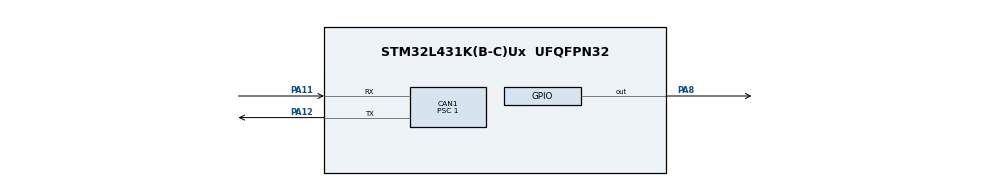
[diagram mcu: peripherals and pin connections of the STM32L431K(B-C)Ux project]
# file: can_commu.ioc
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CAN1.BS1=CAN_BS1_6TQ
CAN1.CalculateBaudRate=500000
CAN1.CalculateTimeBit=2000.00
CAN1.CalculateTimeQuantum=250.0
CAN1.Prescaler=1
Mcu.Family=STM32L4
Mcu.Name=STM32L431K(B-C)Ux
Mcu.Package=UFQFPN32
NVIC.CAN1_RX0_IRQn=true\:0\:0\:false\:false\:true\:true\:true
NVIC.CAN1_TX_IRQn=true\:0\:0\:false\:false\:true\:true\:true
NVIC.PriorityGroup=NVIC_PRIORITYGROUP_4
PA11.Mode=CAN_Activate
PA11.Signal=CAN1_RX
PA12.Mode=CAN_Activate
PA12.Signal=CAN1_TX
PA8.Signal=GPIO_Output
ProjectManager.HeapSize=0x200
ProjectManager.StackSize=0x400
ProjectManager.TargetToolchain=STM32CubeIDE
RCC.HSE_VALUE=8000000
RCC.HSI48_VALUE=48000000
RCC.HSI_VALUE=16000000
RCC.LSE_VALUE=32768
RCC.MSI_VALUE=4000000
RCC.VCOOutputFreq_Value=32000000
board=custom

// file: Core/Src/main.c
/* USER CODE BEGIN Header */
/**
  ******************************************************************************
  * @file           : main.c
  * @brief          : Main program body
  ******************************************************************************
  * @attention
  *
  * <h2><center>&copy; Copyright (c) 2024 STMicroelectronics.
  * All rights reserved.</center></h2>
  *
  * This software component is licensed by ST under BSD 3-Clause license,
  * the "License"; You may not use this file except in compliance with the
  * License. You may obtain a copy of the License at:
  *                        opensource.org/licenses/BSD-3-Clause
  *
  ******************************************************************************
  */
/* USER CODE END Header */
#include "main.h"

CAN_HandleTypeDef hcan1;

/* USER CODE BEGIN PV */
uint8_t RxData[8]; //our buffer to receive data
/* USER CODE END PV */

void SystemClock_Config(void);
static void MX_GPIO_Init(void);
static void MX_CAN1_Init(void);

int main(void)
{

  /* MCU Configuration--------------------------------------------------------*/

  /* Reset of all peripherals, Initializes the Flash interface and the Systick. */
  HAL_Init();

  /* Configure the system clock */
  SystemClock_Config();

  /* Initialize all configured peripherals */
  MX_GPIO_Init();
  MX_CAN1_Init();
  /* USER CODE BEGIN 2 */
  HAL_GPIO_WritePin(GPIOA, GPIO_PIN_8, GPIO_PIN_RESET);
  CAN_FilterTypeDef sFilterConfig ;
  sFilterConfig.FilterMode = CAN_FILTERMODE_IDMASK;
  sFilterConfig.FilterScale = CAN_FILTERSCALE_32BIT;
  sFilterConfig.FilterIdHigh = 0;
  sFilterConfig.FilterIdLow = 0;
  sFilterConfig.FilterMaskIdHigh = 0;
  sFilterConfig.FilterMaskIdLow = 0;
  sFilterConfig.FilterFIFOAssignment = CAN_RX_FIFO0;
  sFilterConfig.FilterActivation = ENABLE;
  sFilterConfig.FilterBank = 1;

  HAL_CAN_ConfigFilter(&hcan1, &sFilterConfig);
  HAL_CAN_Start(&hcan1);
  HAL_CAN_ActivateNotification(&hcan1, CAN_IT_RX_FIFO0_MSG_PENDING);

  /* CAN Tx Message */
  CAN_TxHeaderTypeDef TxHeader;
  uint8_t TxData[8] = {0x01, 0x02, 0x03, 0x04, 0x05, 0x06, 0x07, 0x08};

  TxHeader.StdId = 0x123; // Example standard ID
  TxHeader.IDE = CAN_ID_STD; // Use standard identifier
  TxHeader.RTR = CAN_RTR_DATA; // Data frame
  TxHeader.DLC = 8; // Data length is 8 bytes

  uint32_t TxMailbox = CAN_TX_MAILBOX0;

  /* USER CODE END 2 */

  /* Infinite loop */
  while (1)
  {

    /* USER CODE BEGIN 3 */
//	  HAL_CAN_AddTxMessage(&hcan1, &TxHeader, TxData, &TxMailbox);
//	  HAL_Delay(1000); // Delay between transmissions

  }
  /* USER CODE END 3 */
}

void SystemClock_Config(void)
{
  RCC_OscInitTypeDef RCC_OscInitStruct = {0};
  RCC_ClkInitTypeDef RCC_ClkInitStruct = {0};

  /** Configure the main internal regulator output voltage
  */
  if (HAL_PWREx_ControlVoltageScaling(PWR_REGULATOR_VOLTAGE_SCALE1) != HAL_OK)
  {
    Error_Handler();
  }
  /** Initializes the RCC Oscillators according to the specified parameters
  * in the RCC_OscInitTypeDef structure.
  */
  RCC_OscInitStruct.OscillatorType = RCC_OSCILLATORTYPE_MSI;
  RCC_OscInitStruct.MSIState = RCC_MSI_ON;
  RCC_OscInitStruct.MSICalibrationValue = 0;
  RCC_OscInitStruct.MSIClockRange = RCC_MSIRANGE_6;
  RCC_OscInitStruct.PLL.PLLState = RCC_PLL_NONE;
  if (HAL_RCC_OscConfig(&RCC_OscInitStruct) != HAL_OK)
  {
    Error_Handler();
  }
  /** Initializes the CPU, AHB and APB buses clocks
  */
  RCC_ClkInitStruct.ClockType = RCC_CLOCKTYPE_HCLK|RCC_CLOCKTYPE_SYSCLK
                              |RCC_CLOCKTYPE_PCLK1|RCC_CLOCKTYPE_PCLK2;
  RCC_ClkInitStruct.SYSCLKSource = RCC_SYSCLKSOURCE_MSI;
  RCC_ClkInitStruct.AHBCLKDivider = RCC_SYSCLK_DIV1;
  RCC_ClkInitStruct.APB1CLKDivider = RCC_HCLK_DIV1;
  RCC_ClkInitStruct.APB2CLKDivider = RCC_HCLK_DIV1;

  if (HAL_RCC_ClockConfig(&RCC_ClkInitStruct, FLASH_LATENCY_0) != HAL_OK)
  {
    Error_Handler();
  }
}

static void MX_CAN1_Init(void)
{

  hcan1.Instance = CAN1;
  hcan1.Init.Prescaler = 1;
  hcan1.Init.Mode = CAN_MODE_NORMAL;
  hcan1.Init.SyncJumpWidth = CAN_SJW_1TQ;
  hcan1.Init.TimeSeg1 = CAN_BS1_6TQ;
  hcan1.Init.TimeSeg2 = CAN_BS2_1TQ;
  hcan1.Init.TimeTriggeredMode = DISABLE;
  hcan1.Init.AutoBusOff = DISABLE;
  hcan1.Init.AutoWakeUp = DISABLE;
  hcan1.Init.AutoRetransmission = DISABLE;
  hcan1.Init.ReceiveFifoLocked = DISABLE;
  hcan1.Init.TransmitFifoPriority = DISABLE;
  if (HAL_CAN_Init(&hcan1) != HAL_OK)
  {
    Error_Handler();
  }

}

static void MX_GPIO_Init(void)
{
  GPIO_InitTypeDef GPIO_InitStruct = {0};

  /* GPIO Ports Clock Enable */
  __HAL_RCC_GPIOA_CLK_ENABLE();

  /*Configure GPIO pin Output Level */
  HAL_GPIO_WritePin(GPIOA, GPIO_PIN_8, GPIO_PIN_RESET);

  /*Configure GPIO pin : PA8 */
  GPIO_InitStruct.Pin = GPIO_PIN_8;
  GPIO_InitStruct.Mode = GPIO_MODE_OUTPUT_PP;
  GPIO_InitStruct.Pull = GPIO_NOPULL;
  GPIO_InitStruct.Speed = GPIO_SPEED_FREQ_LOW;
  HAL_GPIO_Init(GPIOA, &GPIO_InitStruct);

}

/* USER CODE BEGIN 4 */
//void HAL_CAN_IRQHandler(CAN_HandleTypeDef *hcan)
void HAL_CAN_RxFifo0MsgPendingCallback(CAN_HandleTypeDef *hcan1)
{
    CAN_RxHeaderTypeDef can_rx_header;
    uint8_t can_rx_data[8]; // Buffer to store received data

    if (HAL_CAN_GetRxMessage(hcan1, CAN_RX_FIFO0, &can_rx_header, can_rx_data) == HAL_OK)
    {
        if (can_rx_header.StdId == 0x300)
        {
            CAN_TxHeaderTypeDef can_tx_header;
            can_tx_header.DLC  = 8;
            can_tx_header.StdId = 0x701;
            can_tx_header.IDE  = CAN_ID_STD;
            can_tx_header.RTR  = CAN_RTR_DATA;
            uint8_t can_tx_data[8] = {0x08, 0x07, 0x06, 0x05, 0x04, 0x03, 0x02, 0x01 };
            uint32_t tx_mail_box = CAN_TX_MAILBOX0;
            HAL_CAN_AddTxMessage(hcan1, &can_tx_header, can_tx_data, &tx_mail_box);
        }
    }
}

/* USER CODE END 4 */

void Error_Handler(void)
{
  __disable_irq();
  while (1)
  {
  }
}

/************************ (C) COPYRIGHT STMicroelectronics *****END OF FILE****/
